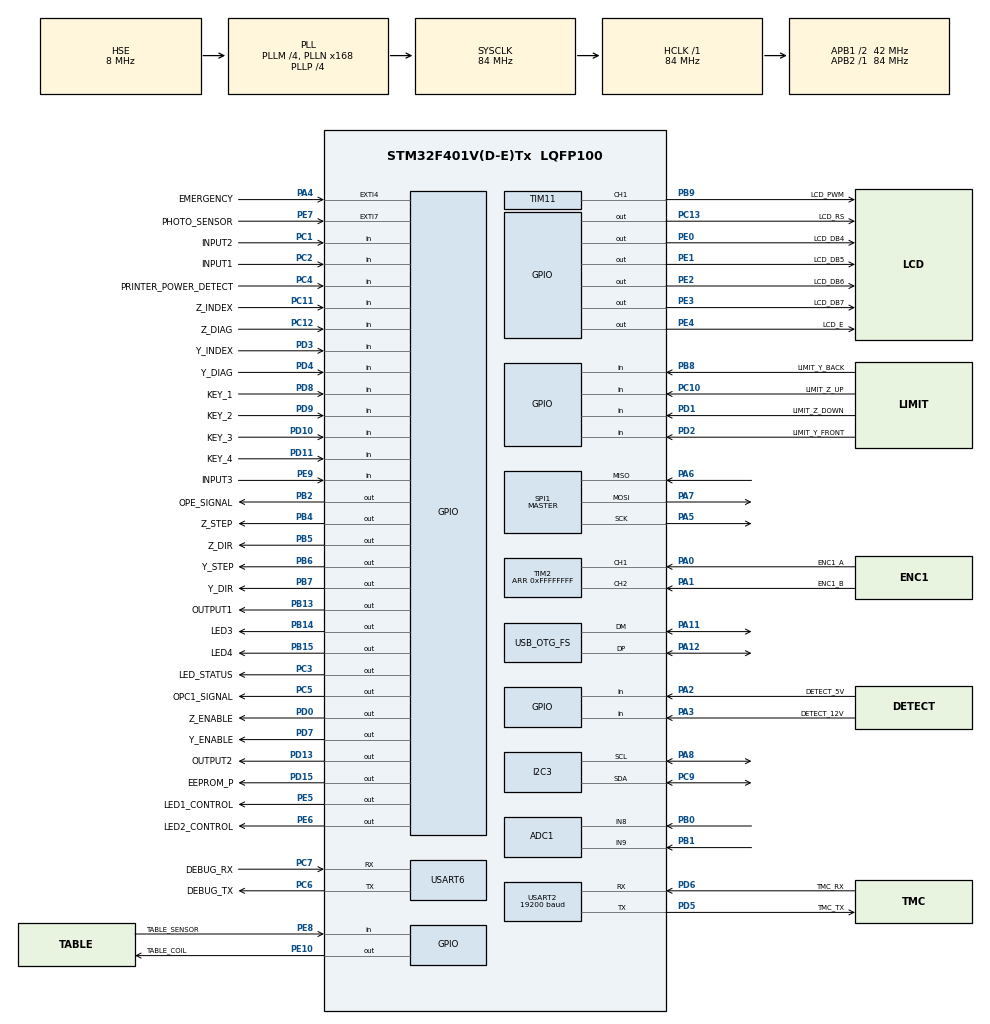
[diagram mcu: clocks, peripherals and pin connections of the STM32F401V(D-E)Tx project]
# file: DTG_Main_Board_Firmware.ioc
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ADC1.Channel-0\#ChannelRegularConversion=ADC_CHANNEL_8
ADC1.NbrOfConversionFlag=1
ADC1.Rank-0\#ChannelRegularConversion=1
ADC1.SamplingTime-0\#ChannelRegularConversion=ADC_SAMPLETIME_3CYCLES
ADC1.master=1
Dma.Request0=USART6_RX
Dma.Request1=USART6_TX
Dma.USART6_RX.0.Direction=DMA_PERIPH_TO_MEMORY
Dma.USART6_RX.0.FIFOMode=DMA_FIFOMODE_DISABLE
Dma.USART6_RX.0.Instance=DMA2_Stream1
Dma.USART6_RX.0.MemDataAlignment=DMA_MDATAALIGN_BYTE
Dma.USART6_RX.0.MemInc=DMA_MINC_ENABLE
Dma.USART6_RX.0.Mode=DMA_NORMAL
Dma.USART6_RX.0.PeriphDataAlignment=DMA_PDATAALIGN_BYTE
Dma.USART6_RX.0.PeriphInc=DMA_PINC_DISABLE
Dma.USART6_RX.0.Priority=DMA_PRIORITY_LOW
Dma.USART6_TX.1.Direction=DMA_MEMORY_TO_PERIPH
Dma.USART6_TX.1.FIFOMode=DMA_FIFOMODE_DISABLE
Dma.USART6_TX.1.Instance=DMA2_Stream6
Dma.USART6_TX.1.MemDataAlignment=DMA_MDATAALIGN_BYTE
Dma.USART6_TX.1.MemInc=DMA_MINC_ENABLE
Dma.USART6_TX.1.Mode=DMA_NORMAL
Dma.USART6_TX.1.PeriphDataAlignment=DMA_PDATAALIGN_BYTE
Dma.USART6_TX.1.PeriphInc=DMA_PINC_DISABLE
Dma.USART6_TX.1.Priority=DMA_PRIORITY_LOW
FREERTOS.Tasks01=main_thread,24,128,mainThread,Default,NULL,Static,defaultTaskBuffer,defaultTaskControlBlock
FREERTOS.configUSE_NEWLIB_REENTRANT=1
FREERTOS.configUSE_POSIX_ERRNO=1
FREERTOS.configUSE_PREEMPTION=0
FREERTOS.configUSE_TICKLESS_IDLE=1
Mcu.Family=STM32F4
Mcu.Name=STM32F401V(D-E)Tx
Mcu.Package=LQFP100
NVIC.DMA2_Stream1_IRQn=true\:5\:0\:false\:false\:true\:true\:false\:true\:true
NVIC.DMA2_Stream6_IRQn=true\:5\:0\:false\:false\:true\:true\:false\:true\:true
NVIC.EXTI4_IRQn=true\:5\:0\:false\:false\:true\:true\:true\:true\:true
NVIC.EXTI9_5_IRQn=true\:5\:0\:false\:false\:true\:true\:true\:true\:true
NVIC.OTG_FS_IRQn=true\:5\:0\:false\:false\:true\:true\:false\:true\:true
NVIC.PriorityGroup=NVIC_PRIORITYGROUP_4
NVIC.TIM1_BRK_TIM9_IRQn=true\:5\:0\:false\:false\:true\:true\:true\:true\:true
NVIC.TIM1_UP_TIM10_IRQn=true\:15\:0\:false\:false\:true\:false\:true\:true\:true
NVIC.TimeBase=TIM1_UP_TIM10_IRQn
NVIC.TimeBaseIP=TIM1
NVIC.USART6_IRQn=true\:5\:0\:false\:false\:true\:true\:true\:true\:true
PA0-WKUP.GPIO_Label=ENC1_A
PA0-WKUP.Signal=S_TIM2_CH1_ETR
PA1.GPIO_Label=ENC1_B
PA1.Signal=S_TIM2_CH2
PA11.Mode=Device_Only
PA11.Signal=USB_OTG_FS_DM
PA12.Mode=Device_Only
PA12.Signal=USB_OTG_FS_DP
PA13.Mode=Trace_Asynchronous_SW
PA13.Signal=SYS_JTMS-SWDIO
PA14.Mode=Trace_Asynchronous_SW
PA14.Signal=SYS_JTCK-SWCLK
PA2.GPIO_Label=DETECT_5V
PA2.Signal=GPIO_Input
PA3.GPIO_Label=DETECT_12V
PA3.Signal=GPIO_Input
PA4.GPIO_Label=EMERGENCY
PA4.GPIO_PuPd=GPIO_NOPULL
PA4.Signal=GPXTI4
PA5.Mode=Full_Duplex_Master
PA5.Signal=SPI1_SCK
PA6.Mode=Full_Duplex_Master
PA6.Signal=SPI1_MISO
PA7.Mode=Full_Duplex_Master
PA7.Signal=SPI1_MOSI
PA8.GPIO_Pu=GPIO_PULLUP
PA8.Mode=I2C
PA8.Signal=I2C3_SCL
PB0.Signal=ADCx_IN8
PB1.Signal=ADCx_IN9
PB13.GPIO_Label=OUTPUT1
PB13.Signal=GPIO_Output
PB14.GPIO_Label=LED3
PB14.Signal=GPIO_Output
PB15.GPIO_Label=LED4
PB15.Signal=GPIO_Output
PB2.GPIO_Label=OPE_SIGNAL
PB2.Signal=GPIO_Output
PB3.Mode=Trace_Asynchronous_SW
PB3.Signal=SYS_JTDO-SWO
PB4.GPIO_Label=Z_STEP
PB4.Signal=GPIO_Output
PB5.GPIO_Label=Z_DIR
PB5.Signal=GPIO_Output
PB6.GPIO_Label=Y_STEP
PB6.Signal=GPIO_Output
PB7.GPIO_Label=Y_DIR
PB7.Signal=GPIO_Output
PB8.GPIO_Label=LIMIT_Y_BACK
PB8.Signal=GPIO_Input
PB9.GPIO_Label=LCD_PWM
PB9.Signal=S_TIM11_CH1
PC1.GPIO_Label=INPUT2
PC1.Signal=GPIO_Input
PC10.GPIO_Label=LIMIT_Z_UP
PC10.Signal=GPIO_Input
PC11.GPIO_Label=Z_INDEX
PC11.Signal=GPIO_Input
PC12.GPIO_Label=Z_DIAG
PC12.Signal=GPIO_Input
PC13-ANTI_TAMP.GPIO_Label=LCD_RS
PC13-ANTI_TAMP.Signal=GPIO_Output
PC2.GPIO_Label=INPUT1
PC2.Signal=GPIO_Input
PC3.GPIO_Label=LED_STATUS
PC3.Signal=GPIO_Output
PC4.GPIO_Label=PRINTER_POWER_DETECT
PC4.Signal=GPIO_Input
PC5.GPIO_Label=OPC1_SIGNAL
PC5.Signal=GPIO_Output
PC6.GPIO_Label=DEBUG_TX
PC6.Mode=Asynchronous
PC6.Signal=USART6_TX
PC7.GPIO_Label=DEBUG_RX
PC7.Mode=Asynchronous
PC7.Signal=USART6_RX
PC9.GPIO_Pu=GPIO_PULLUP
PC9.Mode=I2C
PC9.Signal=I2C3_SDA
PD0.GPIO_Label=Z_ENABLE
PD0.PinState=GPIO_PIN_SET
PD0.Signal=GPIO_Output
PD1.GPIO_Label=LIMIT_Z_DOWN
PD1.Signal=GPIO_Input
PD10.GPIO_Label=KEY_3
PD10.Signal=GPIO_Input
PD11.GPIO_Label=KEY_4
PD11.Signal=GPIO_Input
PD13.GPIO_Label=OUTPUT2
PD13.Signal=GPIO_Output
PD15.GPIO_Label=EEPROM_P
PD15.Signal=GPIO_Output
PD2.GPIO_Label=LIMIT_Y_FRONT
PD2.Signal=GPIO_Input
PD3.GPIO_Label=Y_INDEX
PD3.Signal=GPIO_Input
PD4.GPIO_Label=Y_DIAG
PD4.Signal=GPIO_Input
PD5.GPIO_Label=TMC_TX
PD5.Mode=Asynchronous
PD5.Signal=USART2_TX
PD6.GPIO_Label=TMC_RX
PD6.Mode=Asynchronous
PD6.Signal=USART2_RX
PD7.GPIO_Label=Y_ENABLE
PD7.PinState=GPIO_PIN_SET
PD7.Signal=GPIO_Output
PD8.GPIO_Label=KEY_1
PD8.Signal=GPIO_Input
PD9.GPIO_Label=KEY_2
PD9.Signal=GPIO_Input
PE0.GPIO_Label=LCD_DB4
PE0.Signal=GPIO_Output
PE1.GPIO_Label=LCD_DB5
PE1.Signal=GPIO_Output
PE10.GPIO_Label=TABLE_COIL
PE10.Signal=GPIO_Output
PE2.GPIO_Label=LCD_DB6
PE2.Signal=GPIO_Output
PE3.GPIO_Label=LCD_DB7
PE3.Signal=GPIO_Output
PE4.GPIO_Label=LCD_E
PE4.Signal=GPIO_Output
PE5.GPIO_Label=LED1_CONTROL
PE5.Signal=GPIO_Output
PE6.GPIO_Label=LED2_CONTROL
PE6.Signal=GPIO_Output
PE7.GPIO_Label=PHOTO_SENSOR
PE7.GPIO_ModeDefaultEXTI=GPIO_MODE_IT_RISING
PE7.Signal=GPXTI7
PE8.GPIO_Label=TABLE_SENSOR
PE8.Signal=GPIO_Input
PE9.GPIO_Label=INPUT3
PE9.Signal=GPIO_Input
PH0\ -\ OSC_IN.Mode=HSE-External-Oscillator
PH0\ -\ OSC_IN.Signal=RCC_OSC_IN
PH1\ -\ OSC_OUT.Mode=HSE-External-Oscillator
PH1\ -\ OSC_OUT.Signal=RCC_OSC_OUT
ProjectManager.HeapSize=0x600
ProjectManager.StackSize=0x400
ProjectManager.TargetToolchain=STM32CubeIDE
RCC.48MHZClocksFreq_Value=48000000
RCC.AHBFreq_Value=84000000
RCC.APB1CLKDivider=RCC_HCLK_DIV2
RCC.APB1Freq_Value=42000000
RCC.APB1TimFreq_Value=84000000
RCC.APB2Freq_Value=84000000
RCC.APB2TimFreq_Value=84000000
RCC.CortexFreq_Value=84000000
RCC.HCLKFreq_Value=84000000
RCC.HSE_VALUE=8000000
RCC.HSI_VALUE=16000000
RCC.LSE_VALUE=32768
RCC.PLLM=4
RCC.PLLN=168
RCC.PLLP=RCC_PLLP_DIV4
RCC.PLLQ=7
RCC.SYSCLKFreq_VALUE=84000000
RCC.SYSCLKSource=RCC_SYSCLKSOURCE_PLLCLK
RCC.VCOOutputFreq_Value=336000000
SH.ADCx_IN8.0=ADC1_IN8,IN8
SH.ADCx_IN9.0=ADC1_IN9,IN9
SH.S_TIM11_CH1.0=TIM11_CH1,PWM Generation1 CH1
SH.S_TIM2_CH1_ETR.0=TIM2_CH1,Encoder_Interface
SH.S_TIM2_CH2.0=TIM2_CH2,Encoder_Interface
SPI1.Direction=SPI_DIRECTION_2LINES
SPI1.Mode=SPI_MODE_MASTER
SPI1.VirtualType=VM_MASTER
TIM10.ClockDivision=TIM_CLOCKDIVISION_DIV1
TIM10.Period=65535
TIM10.Prescaler=167
TIM11.Channel=TIM_CHANNEL_1
TIM2.EncoderMode=TIM_ENCODERMODE_TI12
TIM2.IC1Filter=15
TIM2.IC2Filter=15
TIM2.Period=0xFFFFFFFF
TIM9.Period=65535
TIM9.Prescaler=167
USART2.BaudRate=19200
USART2.VirtualMode=VM_ASYNC
USART6.VirtualMode=VM_ASYNC
USB_DEVICE.CLASS_NAME_FS=CDC
USB_DEVICE.VirtualMode-CDC_FS=Cdc
USB_DEVICE.VirtualModeFS=Cdc_FS
USB_OTG_FS.VirtualMode=Device_Only
VP_FREERTOS_VS_CMSIS_V2.Mode=CMSIS_V2
VP_SYS_VS_tim1.Mode=TIM1
VP_TIM10_VS_ClockSourceINT.Mode=Enable_Timer
VP_TIM11_VS_ClockSourceINT.Mode=Enable_Timer
VP_TIM9_VS_ClockSourceINT.Mode=Internal
VP_USB_DEVICE_VS_USB_DEVICE_CDC_FS.Mode=CDC_FS
board=custom

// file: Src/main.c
/* USER CODE BEGIN Header */
/**
  ******************************************************************************
  * @file           : main.c
  * @brief          : Main program body
  ******************************************************************************
  * @attention
  *
  * <h2><center>&copy; Copyright (c) 2020 STMicroelectronics.
  * All rights reserved.</center></h2>
  *
  * This software component is licensed by ST under Ultimate Liberty license
  * SLA0044, the "License"; You may not use this file except in compliance with
  * the License. You may obtain a copy of the License at:
  *                             www.st.com/SLA0044
  *
  ******************************************************************************
  */
/* USER CODE END Header */
#include "main.h"
#include "cmsis_os.h"
#include "usb_device.h"

/* USER CODE BEGIN Includes */
#include "scheduler/task_scheduler.h"
#include "scheduler/tasks.h"
#include "UART_DMA.h"
/* USER CODE END Includes */

typedef StaticTask_t osStaticThreadDef_t;

ADC_HandleTypeDef hadc1;

I2C_HandleTypeDef hi2c3;

SPI_HandleTypeDef hspi1;

TIM_HandleTypeDef htim2;
TIM_HandleTypeDef htim9;
TIM_HandleTypeDef htim10;
TIM_HandleTypeDef htim11;

UART_HandleTypeDef huart2;
UART_HandleTypeDef huart6;
DMA_HandleTypeDef hdma_usart6_rx;
DMA_HandleTypeDef hdma_usart6_tx;

/* Definitions for main_thread */
osThreadId_t main_threadHandle;
uint32_t defaultTaskBuffer[ 128 ];
osStaticThreadDef_t defaultTaskControlBlock;
const osThreadAttr_t main_thread_attributes = {
  .name = "main_thread",
  .cb_mem = &defaultTaskControlBlock,
  .cb_size = sizeof(defaultTaskControlBlock),
  .stack_mem = &defaultTaskBuffer[0],
  .stack_size = sizeof(defaultTaskBuffer),
  .priority = (osPriority_t) osPriorityNormal,
};
/* USER CODE BEGIN PV */
UARTDMA_HandleTypeDef huartdma;
/* USER CODE END PV */

void SystemClock_Config(void);
static void MX_GPIO_Init(void);
static void MX_DMA_Init(void);
static void MX_I2C3_Init(void);
static void MX_SPI1_Init(void);
static void MX_TIM2_Init(void);
static void MX_TIM10_Init(void);
static void MX_TIM11_Init(void);
static void MX_USART2_UART_Init(void);
static void MX_ADC1_Init(void);
static void MX_TIM9_Init(void);
static void MX_USART6_UART_Init(void);
void mainThread(void *argument);

/* USER CODE BEGIN 0 */
void print(const char *s) {
  while (*s!='\0') {
	  HAL_UART_Transmit(&huart2, (uint8_t *)s++, 1, 10);
	  //TODO: Use DMA or IT to send data
  }
}

/* USER CODE END 0 */

int main(void)
{

  /* MCU Configuration--------------------------------------------------------*/

  /* Reset of all peripherals, Initializes the Flash interface and the Systick. */
  HAL_Init();

  /* Configure the system clock */
  SystemClock_Config();

  /* Initialize all configured peripherals */
  MX_GPIO_Init();
  MX_DMA_Init();
  MX_I2C3_Init();
  MX_SPI1_Init();
  MX_TIM2_Init();
  MX_TIM10_Init();
  MX_TIM11_Init();
  MX_USART2_UART_Init();
  MX_ADC1_Init();
  MX_TIM9_Init();
  MX_USART6_UART_Init();
  /* USER CODE BEGIN 2 */
  //Start encoder for EPSON printer
  HAL_TIM_Encoder_Start(&htim2, TIM_CHANNEL_ALL);

  //Start UART6 RX DMA communication
  UARTDMA_Init(&huartdma, &huart6);

  //Initialize tasks
  tasksInitialize();
  /* USER CODE END 2 */

  /* Init scheduler */
  osKernelInitialize();

  /* Create the thread(s) */
  /* creation of main_thread */
  main_threadHandle = osThreadNew(mainThread, NULL, &main_thread_attributes);

  /* Start scheduler */
  osKernelStart();
  /* We should never get here as control is now taken by the scheduler */
  /* Infinite loop */
  /* USER CODE BEGIN WHILE */
  while (1)
  {
	//Start Schedulers
	tasksScheduler();
    /* USER CODE END WHILE */

  }
}

void SystemClock_Config(void)
{
  RCC_OscInitTypeDef RCC_OscInitStruct = {0};
  RCC_ClkInitTypeDef RCC_ClkInitStruct = {0};

  /** Configure the main internal regulator output voltage
  */
  __HAL_RCC_PWR_CLK_ENABLE();
  __HAL_PWR_VOLTAGESCALING_CONFIG(PWR_REGULATOR_VOLTAGE_SCALE2);

  /** Initializes the RCC Oscillators according to the specified parameters
  * in the RCC_OscInitTypeDef structure.
  */
  RCC_OscInitStruct.OscillatorType = RCC_OSCILLATORTYPE_HSE;
  RCC_OscInitStruct.HSEState = RCC_HSE_ON;
  RCC_OscInitStruct.PLL.PLLState = RCC_PLL_ON;
  RCC_OscInitStruct.PLL.PLLSource = RCC_PLLSOURCE_HSE;
  RCC_OscInitStruct.PLL.PLLM = 4;
  RCC_OscInitStruct.PLL.PLLN = 168;
  RCC_OscInitStruct.PLL.PLLP = RCC_PLLP_DIV4;
  RCC_OscInitStruct.PLL.PLLQ = 7;
  if (HAL_RCC_OscConfig(&RCC_OscInitStruct) != HAL_OK)
  {
    Error_Handler();
  }

  /** Initializes the CPU, AHB and APB buses clocks
  */
  RCC_ClkInitStruct.ClockType = RCC_CLOCKTYPE_HCLK|RCC_CLOCKTYPE_SYSCLK
                              |RCC_CLOCKTYPE_PCLK1|RCC_CLOCKTYPE_PCLK2;
  RCC_ClkInitStruct.SYSCLKSource = RCC_SYSCLKSOURCE_PLLCLK;
  RCC_ClkInitStruct.AHBCLKDivider = RCC_SYSCLK_DIV1;
  RCC_ClkInitStruct.APB1CLKDivider = RCC_HCLK_DIV2;
  RCC_ClkInitStruct.APB2CLKDivider = RCC_HCLK_DIV1;

  if (HAL_RCC_ClockConfig(&RCC_ClkInitStruct, FLASH_LATENCY_2) != HAL_OK)
  {
    Error_Handler();
  }
}

static void MX_ADC1_Init(void)
{

  ADC_ChannelConfTypeDef sConfig = {0};

  /** Configure the global features of the ADC (Clock, Resolution, Data Alignment and number of conversion)
  */
  hadc1.Instance = ADC1;
  hadc1.Init.ClockPrescaler = ADC_CLOCK_SYNC_PCLK_DIV4;
  hadc1.Init.Resolution = ADC_RESOLUTION_12B;
  hadc1.Init.ScanConvMode = DISABLE;
  hadc1.Init.ContinuousConvMode = DISABLE;
  hadc1.Init.DiscontinuousConvMode = DISABLE;
  hadc1.Init.ExternalTrigConvEdge = ADC_EXTERNALTRIGCONVEDGE_NONE;
  hadc1.Init.ExternalTrigConv = ADC_SOFTWARE_START;
  hadc1.Init.DataAlign = ADC_DATAALIGN_RIGHT;
  hadc1.Init.NbrOfConversion = 1;
  hadc1.Init.DMAContinuousRequests = DISABLE;
  hadc1.Init.EOCSelection = ADC_EOC_SINGLE_CONV;
  if (HAL_ADC_Init(&hadc1) != HAL_OK)
  {
    Error_Handler();
  }

  /** Configure for the selected ADC regular channel its corresponding rank in the sequencer and its sample time.
  */
  sConfig.Channel = ADC_CHANNEL_8;
  sConfig.Rank = 1;
  sConfig.SamplingTime = ADC_SAMPLETIME_3CYCLES;
  if (HAL_ADC_ConfigChannel(&hadc1, &sConfig) != HAL_OK)
  {
    Error_Handler();
  }

}

static void MX_I2C3_Init(void)
{

  hi2c3.Instance = I2C3;
  hi2c3.Init.ClockSpeed = 100000;
  hi2c3.Init.DutyCycle = I2C_DUTYCYCLE_2;
  hi2c3.Init.OwnAddress1 = 0;
  hi2c3.Init.AddressingMode = I2C_ADDRESSINGMODE_7BIT;
  hi2c3.Init.DualAddressMode = I2C_DUALADDRESS_DISABLE;
  hi2c3.Init.OwnAddress2 = 0;
  hi2c3.Init.GeneralCallMode = I2C_GENERALCALL_DISABLE;
  hi2c3.Init.NoStretchMode = I2C_NOSTRETCH_DISABLE;
  if (HAL_I2C_Init(&hi2c3) != HAL_OK)
  {
    Error_Handler();
  }

}

static void MX_SPI1_Init(void)
{

  /* SPI1 parameter configuration*/
  hspi1.Instance = SPI1;
  hspi1.Init.Mode = SPI_MODE_MASTER;
  hspi1.Init.Direction = SPI_DIRECTION_2LINES;
  hspi1.Init.DataSize = SPI_DATASIZE_8BIT;
  hspi1.Init.CLKPolarity = SPI_POLARITY_LOW;
  hspi1.Init.CLKPhase = SPI_PHASE_1EDGE;
  hspi1.Init.NSS = SPI_NSS_SOFT;
  hspi1.Init.BaudRatePrescaler = SPI_BAUDRATEPRESCALER_2;
  hspi1.Init.FirstBit = SPI_FIRSTBIT_MSB;
  hspi1.Init.TIMode = SPI_TIMODE_DISABLE;
  hspi1.Init.CRCCalculation = SPI_CRCCALCULATION_DISABLE;
  hspi1.Init.CRCPolynomial = 10;
  if (HAL_SPI_Init(&hspi1) != HAL_OK)
  {
    Error_Handler();
  }

}

static void MX_TIM2_Init(void)
{

  TIM_Encoder_InitTypeDef sConfig = {0};
  TIM_MasterConfigTypeDef sMasterConfig = {0};

  htim2.Instance = TIM2;
  htim2.Init.Prescaler = 0;
  htim2.Init.CounterMode = TIM_COUNTERMODE_UP;
  htim2.Init.Period = 0xFFFFFFFF;
  htim2.Init.ClockDivision = TIM_CLOCKDIVISION_DIV1;
  htim2.Init.AutoReloadPreload = TIM_AUTORELOAD_PRELOAD_DISABLE;
  sConfig.EncoderMode = TIM_ENCODERMODE_TI12;
  sConfig.IC1Polarity = TIM_ICPOLARITY_RISING;
  sConfig.IC1Selection = TIM_ICSELECTION_DIRECTTI;
  sConfig.IC1Prescaler = TIM_ICPSC_DIV1;
  sConfig.IC1Filter = 15;
  sConfig.IC2Polarity = TIM_ICPOLARITY_RISING;
  sConfig.IC2Selection = TIM_ICSELECTION_DIRECTTI;
  sConfig.IC2Prescaler = TIM_ICPSC_DIV1;
  sConfig.IC2Filter = 15;
  if (HAL_TIM_Encoder_Init(&htim2, &sConfig) != HAL_OK)
  {
    Error_Handler();
  }
  sMasterConfig.MasterOutputTrigger = TIM_TRGO_RESET;
  sMasterConfig.MasterSlaveMode = TIM_MASTERSLAVEMODE_DISABLE;
  if (HAL_TIMEx_MasterConfigSynchronization(&htim2, &sMasterConfig) != HAL_OK)
  {
    Error_Handler();
  }

}

static void MX_TIM9_Init(void)
{

  TIM_ClockConfigTypeDef sClockSourceConfig = {0};

  htim9.Instance = TIM9;
  htim9.Init.Prescaler = 167;
  htim9.Init.CounterMode = TIM_COUNTERMODE_UP;
  htim9.Init.Period = 65535;
  htim9.Init.ClockDivision = TIM_CLOCKDIVISION_DIV1;
  htim9.Init.AutoReloadPreload = TIM_AUTORELOAD_PRELOAD_DISABLE;
  if (HAL_TIM_Base_Init(&htim9) != HAL_OK)
  {
    Error_Handler();
  }
  sClockSourceConfig.ClockSource = TIM_CLOCKSOURCE_INTERNAL;
  if (HAL_TIM_ConfigClockSource(&htim9, &sClockSourceConfig) != HAL_OK)
  {
    Error_Handler();
  }

}

static void MX_TIM10_Init(void)
{

  htim10.Instance = TIM10;
  htim10.Init.Prescaler = 167;
  htim10.Init.CounterMode = TIM_COUNTERMODE_UP;
  htim10.Init.Period = 65535;
  htim10.Init.ClockDivision = TIM_CLOCKDIVISION_DIV1;
  htim10.Init.AutoReloadPreload = TIM_AUTORELOAD_PRELOAD_DISABLE;
  if (HAL_TIM_Base_Init(&htim10) != HAL_OK)
  {
    Error_Handler();
  }

}

static void MX_TIM11_Init(void)
{

  TIM_OC_InitTypeDef sConfigOC = {0};

  htim11.Instance = TIM11;
  htim11.Init.Prescaler = 0;
  htim11.Init.CounterMode = TIM_COUNTERMODE_UP;
  htim11.Init.Period = 65535;
  htim11.Init.ClockDivision = TIM_CLOCKDIVISION_DIV1;
  htim11.Init.AutoReloadPreload = TIM_AUTORELOAD_PRELOAD_DISABLE;
  if (HAL_TIM_Base_Init(&htim11) != HAL_OK)
  {
    Error_Handler();
  }
  if (HAL_TIM_PWM_Init(&htim11) != HAL_OK)
  {
    Error_Handler();
  }
  sConfigOC.OCMode = TIM_OCMODE_PWM1;
  sConfigOC.Pulse = 0;
  sConfigOC.OCPolarity = TIM_OCPOLARITY_HIGH;
  sConfigOC.OCFastMode = TIM_OCFAST_DISABLE;
  if (HAL_TIM_PWM_ConfigChannel(&htim11, &sConfigOC, TIM_CHANNEL_1) != HAL_OK)
  {
    Error_Handler();
  }
  HAL_TIM_MspPostInit(&htim11);

}

static void MX_USART2_UART_Init(void)
{

  huart2.Instance = USART2;
  huart2.Init.BaudRate = 19200;
  huart2.Init.WordLength = UART_WORDLENGTH_8B;
  huart2.Init.StopBits = UART_STOPBITS_1;
  huart2.Init.Parity = UART_PARITY_NONE;
  huart2.Init.Mode = UART_MODE_TX_RX;
  huart2.Init.HwFlowCtl = UART_HWCONTROL_NONE;
  huart2.Init.OverSampling = UART_OVERSAMPLING_16;
  if (HAL_UART_Init(&huart2) != HAL_OK)
  {
    Error_Handler();
  }

}

static void MX_USART6_UART_Init(void)
{

  huart6.Instance = USART6;
  huart6.Init.BaudRate = 115200;
  huart6.Init.WordLength = UART_WORDLENGTH_8B;
  huart6.Init.StopBits = UART_STOPBITS_1;
  huart6.Init.Parity = UART_PARITY_NONE;
  huart6.Init.Mode = UART_MODE_TX_RX;
  huart6.Init.HwFlowCtl = UART_HWCONTROL_NONE;
  huart6.Init.OverSampling = UART_OVERSAMPLING_16;
  if (HAL_UART_Init(&huart6) != HAL_OK)
  {
    Error_Handler();
  }

}

static void MX_DMA_Init(void)
{

  /* DMA controller clock enable */
  __HAL_RCC_DMA2_CLK_ENABLE();

  /* DMA interrupt init */
  /* DMA2_Stream1_IRQn interrupt configuration */
  HAL_NVIC_SetPriority(DMA2_Stream1_IRQn, 5, 0);
  HAL_NVIC_EnableIRQ(DMA2_Stream1_IRQn);
  /* DMA2_Stream6_IRQn interrupt configuration */
  HAL_NVIC_SetPriority(DMA2_Stream6_IRQn, 5, 0);
  HAL_NVIC_EnableIRQ(DMA2_Stream6_IRQn);

}

static void MX_GPIO_Init(void)
{
  GPIO_InitTypeDef GPIO_InitStruct = {0};

  /* GPIO Ports Clock Enable */
  __HAL_RCC_GPIOE_CLK_ENABLE();
  __HAL_RCC_GPIOC_CLK_ENABLE();
  __HAL_RCC_GPIOH_CLK_ENABLE();
  __HAL_RCC_GPIOA_CLK_ENABLE();
  __HAL_RCC_GPIOB_CLK_ENABLE();
  __HAL_RCC_GPIOD_CLK_ENABLE();

  /*Configure GPIO pin Output Level */
  HAL_GPIO_WritePin(GPIOE, LCD_DB6_Pin|LCD_DB7_Pin|LCD_E_Pin|LED1_CONTROL_Pin
                          |LED2_CONTROL_Pin|TABLE_COIL_Pin|LCD_DB4_Pin|LCD_DB5_Pin, GPIO_PIN_RESET);

  /*Configure GPIO pin Output Level */
  HAL_GPIO_WritePin(GPIOC, LCD_RS_Pin|LED_STATUS_Pin|OPC1_SIGNAL_Pin, GPIO_PIN_RESET);

  /*Configure GPIO pin Output Level */
  HAL_GPIO_WritePin(GPIOB, OPE_SIGNAL_Pin|OUTPUT1_Pin|LED3_Pin|LED4_Pin
                          |Z_STEP_Pin|Z_DIR_Pin|Y_STEP_Pin|Y_DIR_Pin, GPIO_PIN_RESET);

  /*Configure GPIO pin Output Level */
  HAL_GPIO_WritePin(GPIOD, OUTPUT2_Pin|EEPROM_P_Pin, GPIO_PIN_RESET);

  /*Configure GPIO pin Output Level */
  HAL_GPIO_WritePin(GPIOD, Z_ENABLE_Pin|Y_ENABLE_Pin, GPIO_PIN_SET);

  /*Configure GPIO pins : LCD_DB6_Pin LCD_DB7_Pin LCD_E_Pin LED1_CONTROL_Pin
                           LED2_CONTROL_Pin TABLE_COIL_Pin LCD_DB4_Pin LCD_DB5_Pin */
  GPIO_InitStruct.Pin = LCD_DB6_Pin|LCD_DB7_Pin|LCD_E_Pin|LED1_CONTROL_Pin
                          |LED2_CONTROL_Pin|TABLE_COIL_Pin|LCD_DB4_Pin|LCD_DB5_Pin;
  GPIO_InitStruct.Mode = GPIO_MODE_OUTPUT_PP;
  GPIO_InitStruct.Pull = GPIO_NOPULL;
  GPIO_InitStruct.Speed = GPIO_SPEED_FREQ_LOW;
  HAL_GPIO_Init(GPIOE, &GPIO_InitStruct);

  /*Configure GPIO pins : LCD_RS_Pin LED_STATUS_Pin OPC1_SIGNAL_Pin */
  GPIO_InitStruct.Pin = LCD_RS_Pin|LED_STATUS_Pin|OPC1_SIGNAL_Pin;
  GPIO_InitStruct.Mode = GPIO_MODE_OUTPUT_PP;
  GPIO_InitStruct.Pull = GPIO_NOPULL;
  GPIO_InitStruct.Speed = GPIO_SPEED_FREQ_LOW;
  HAL_GPIO_Init(GPIOC, &GPIO_InitStruct);

  /*Configure GPIO pins : INPUT2_Pin INPUT1_Pin PRINTER_POWER_DETECT_Pin LIMIT_Z_UP_Pin
                           Z_INDEX_Pin Z_DIAG_Pin */
  GPIO_InitStruct.Pin = INPUT2_Pin|INPUT1_Pin|PRINTER_POWER_DETECT_Pin|LIMIT_Z_UP_Pin
                          |Z_INDEX_Pin|Z_DIAG_Pin;
  GPIO_InitStruct.Mode = GPIO_MODE_INPUT;
  GPIO_InitStruct.Pull = GPIO_NOPULL;
  HAL_GPIO_Init(GPIOC, &GPIO_InitStruct);

  /*Configure GPIO pins : DETECT_5V_Pin DETECT_12V_Pin */
  GPIO_InitStruct.Pin = DETECT_5V_Pin|DETECT_12V_Pin;
  GPIO_InitStruct.Mode = GPIO_MODE_INPUT;
  GPIO_InitStruct.Pull = GPIO_NOPULL;
  HAL_GPIO_Init(GPIOA, &GPIO_InitStruct);

  /*Configure GPIO pin : EMERGENCY_Pin */
  GPIO_InitStruct.Pin = EMERGENCY_Pin;
  GPIO_InitStruct.Mode = GPIO_MODE_IT_RISING;
  GPIO_InitStruct.Pull = GPIO_NOPULL;
  HAL_GPIO_Init(EMERGENCY_GPIO_Port, &GPIO_InitStruct);

  /*Configure GPIO pins : OPE_SIGNAL_Pin OUTPUT1_Pin LED3_Pin LED4_Pin
                           Z_STEP_Pin Z_DIR_Pin Y_STEP_Pin Y_DIR_Pin */
  GPIO_InitStruct.Pin = OPE_SIGNAL_Pin|OUTPUT1_Pin|LED3_Pin|LED4_Pin
                          |Z_STEP_Pin|Z_DIR_Pin|Y_STEP_Pin|Y_DIR_Pin;
  GPIO_InitStruct.Mode = GPIO_MODE_OUTPUT_PP;
  GPIO_InitStruct.Pull = GPIO_NOPULL;
  GPIO_InitStruct.Speed = GPIO_SPEED_FREQ_LOW;
  HAL_GPIO_Init(GPIOB, &GPIO_InitStruct);

  /*Configure GPIO pin : PHOTO_SENSOR_Pin */
  GPIO_InitStruct.Pin = PHOTO_SENSOR_Pin;
  GPIO_InitStruct.Mode = GPIO_MODE_IT_RISING;
  GPIO_InitStruct.Pull = GPIO_NOPULL;
  HAL_GPIO_Init(PHOTO_SENSOR_GPIO_Port, &GPIO_InitStruct);

  /*Configure GPIO pins : TABLE_SENSOR_Pin INPUT3_Pin */
  GPIO_InitStruct.Pin = TABLE_SENSOR_Pin|INPUT3_Pin;
  GPIO_InitStruct.Mode = GPIO_MODE_INPUT;
  GPIO_InitStruct.Pull = GPIO_NOPULL;
  HAL_GPIO_Init(GPIOE, &GPIO_InitStruct);

  /*Configure GPIO pins : KEY_1_Pin KEY_2_Pin KEY_3_Pin KEY_4_Pin
                           LIMIT_Z_DOWN_Pin LIMIT_Y_FRONT_Pin Y_INDEX_Pin Y_DIAG_Pin */
  GPIO_InitStruct.Pin = KEY_1_Pin|KEY_2_Pin|KEY_3_Pin|KEY_4_Pin
                          |LIMIT_Z_DOWN_Pin|LIMIT_Y_FRONT_Pin|Y_INDEX_Pin|Y_DIAG_Pin;
  GPIO_InitStruct.Mode = GPIO_MODE_INPUT;
  GPIO_InitStruct.Pull = GPIO_NOPULL;
  HAL_GPIO_Init(GPIOD, &GPIO_InitStruct);

  /*Configure GPIO pins : OUTPUT2_Pin EEPROM_P_Pin Z_ENABLE_Pin Y_ENABLE_Pin */
  GPIO_InitStruct.Pin = OUTPUT2_Pin|EEPROM_P_Pin|Z_ENABLE_Pin|Y_ENABLE_Pin;
  GPIO_InitStruct.Mode = GPIO_MODE_OUTPUT_PP;
  GPIO_InitStruct.Pull = GPIO_NOPULL;
  GPIO_InitStruct.Speed = GPIO_SPEED_FREQ_LOW;
  HAL_GPIO_Init(GPIOD, &GPIO_InitStruct);

  /*Configure GPIO pin : LIMIT_Y_BACK_Pin */
  GPIO_InitStruct.Pin = LIMIT_Y_BACK_Pin;
  GPIO_InitStruct.Mode = GPIO_MODE_INPUT;
  GPIO_InitStruct.Pull = GPIO_NOPULL;
  HAL_GPIO_Init(LIMIT_Y_BACK_GPIO_Port, &GPIO_InitStruct);

  /* EXTI interrupt init*/
  HAL_NVIC_SetPriority(EXTI4_IRQn, 5, 0);
  HAL_NVIC_EnableIRQ(EXTI4_IRQn);

  HAL_NVIC_SetPriority(EXTI9_5_IRQn, 5, 0);
  HAL_NVIC_EnableIRQ(EXTI9_5_IRQn);

}

void mainThread(void *argument)
{
  /* init code for USB_DEVICE */
  MX_USB_DEVICE_Init();
  for(;;)
  {
    osDelay(1);
  }
}

void HAL_TIM_PeriodElapsedCallback(TIM_HandleTypeDef *htim)
{
  if (htim->Instance == TIM1) {
    HAL_IncTick();
  }
}

void Error_Handler(void)
{
}

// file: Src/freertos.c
/* USER CODE BEGIN Header */
/**
  ******************************************************************************
  * File Name          : freertos.c
  * Description        : Code for freertos applications
  ******************************************************************************
  * @attention
  *
  * Copyright (c) 2023 STMicroelectronics.
  * All rights reserved.
  *
  * This software is licensed under terms that can be found in the LICENSE file
  * in the root directory of this software component.
  * If no LICENSE file comes with this software, it is provided AS-IS.
  *
  ******************************************************************************
  */
/* USER CODE END Header */

#include "FreeRTOS.h"
#include "task.h"
#include "main.h"

/* USER CODE BEGIN PREPOSTSLEEP */
__weak void PreSleepProcessing(uint32_t ulExpectedIdleTime)
{
/* place for user code */
}

__weak void PostSleepProcessing(uint32_t ulExpectedIdleTime)
{
/* place for user code */
}
/* USER CODE END PREPOSTSLEEP */
